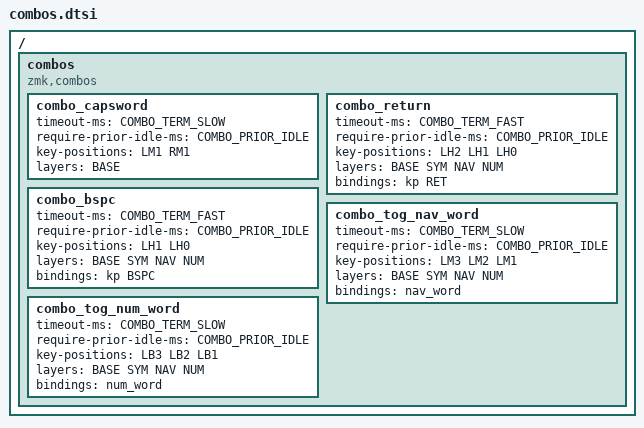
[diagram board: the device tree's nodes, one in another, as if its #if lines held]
#define COMBO_TERM_FAST 35
#define COMBO_TERM_SLOW 40
#define COMBO_PRIOR_IDLE 100

/ {
  combos {
    compatible = "zmk,combos";

//     combo_bracket_v_round_l {
//       timeout-ms = <COMBO_TERM_FAST>;
//       require-prior-idle-ms = <COMBO_PRIOR_IDLE>;
//       key-positions = <LT1 LM1>;
  //     layers = <BASE BASE_QWERTY SYM NUM NUM_WORD>; - was every time below
//       layers = <BASE SYM NAV NUM>; 
//       bindings = <&kp LPAR>;
//     };

    combo_capsword {
      timeout-ms = <COMBO_TERM_SLOW>;
      require-prior-idle-ms = <COMBO_PRIOR_IDLE>;
      key-positions = <LM1 RM1>;
      layers = <BASE>;

// #ifdef HAS_CAPSLOCK
//       bindings = <&caps_word_capslock >;
// #else
//       bindings = <&caps_word>;
// #endif
    };

    combo_return {
      timeout-ms = <COMBO_TERM_FAST>;
      require-prior-idle-ms = <COMBO_PRIOR_IDLE>;
      key-positions = <LH2 LH1 LH0>;
      layers = <BASE SYM NAV NUM>; 
      bindings = <&kp RET>;
    };

    combo_bspc {
      timeout-ms = <COMBO_TERM_FAST>;
      require-prior-idle-ms = <COMBO_PRIOR_IDLE>;
      key-positions = <LH1 LH0>;
      layers = <BASE SYM NAV NUM>; 
      bindings = <&kp BSPC>;
    };

    combo_tog_nav_word {
      timeout-ms = <COMBO_TERM_SLOW>;
      require-prior-idle-ms = <COMBO_PRIOR_IDLE>;
      key-positions = <LM3 LM2 LM1>;
      layers = <BASE SYM NAV NUM>; 

      #ifdef HAS_UROB
        bindings = <&nav_word>;
      #else
        bindings = <&tog NAV_WORD>;
      #endif

    };

    combo_tog_num_word {
      timeout-ms = <COMBO_TERM_SLOW>;
      require-prior-idle-ms = <COMBO_PRIOR_IDLE>;
      key-positions = <LB3 LB2 LB1>;
      layers = <BASE SYM NAV NUM>; 

      #ifdef HAS_UROB
        bindings = <&num_word>;
      #else
        bindings = <&tog NUM_WORD>;
      #endif

    };

// #ifdef HAS_MOUSE_TP
//     combo_tog_mouse_settings_l {
//       timeout-ms = <COMBO_TERM_SLOW>;
//       // require-prior-idle-ms = <COMBO_PRIOR_IDLE>;
//       key-positions = <LT2 LT3 LT4>;
//       layers = <BASE SYM NAV NUM>; 
//       bindings = <&tog MOUSE_TP_SET>;
//     };

//     combo_tog_mouse_settings_r {
//       timeout-ms = <COMBO_TERM_SLOW>;
//       // require-prior-idle-ms = <COMBO_PRIOR_IDLE>;
//       key-positions = <RT2 RT3 RT4>;
//       layers = <BASE SYM NAV NUM>; 
//       bindings = <&tog MOUSE_TP_SET>;
//     };
// #endif

// #ifdef HAS_MOUSE_KEYS
//     combo_tog_mouse_keys_l {
//       timeout-ms = <COMBO_TERM_SLOW>;
//       // require-prior-idle-ms = <COMBO_PRIOR_IDLE>;
//       key-positions = <LM2 LM3 LM4>;
//       layers = <BASE SYM NAV NUM>; 
//       bindings = <&tog MOUSE_KEYS>;
//     };

//     combo_tog_mouse_keys_r {
//       timeout-ms = <COMBO_TERM_SLOW>;
//       // require-prior-idle-ms = <COMBO_PRIOR_IDLE>;
//       key-positions = <RM2 RM3 RM4>;
//       layers = <BASE SYM NAV NUM>; 
//       bindings = <&tog MOUSE_KEYS>;
//     };
// #endif

  };
};
